# MKV46F16 register map
Vendor: Freescale Semiconductor, Inc.; Series: Kinetis_V; File version: 1.6
CPU: CM4 r0p1, little endian, no MPU, FPU, VTOR, 4 interrupt priority bits
Registers are 32-bit, read-write, reset 0x0 unless marked. A register's access mark holds for its fields unless they carry their own. Offsets are from the block's base; [hi:lo] are bit positions; {n}, {i} and the like mark numbered series; 'fields as' and 'values as' point back to an identical list.

## PWMA — Pulse Width Modulator with nano edge placement
Base 0x40033000; register names take the prefix PWMA_
{0x0+0x60*i} SM{i}CNT (i=0..3) 16-bit ro — Counter Register
  [15:0] CNT — Counter Register Bits
{0x2+0x60*i} SM{i}INIT (i=0..3) 16-bit — Initial Count Register
  [15:0] INIT — Initial Count Register Bits
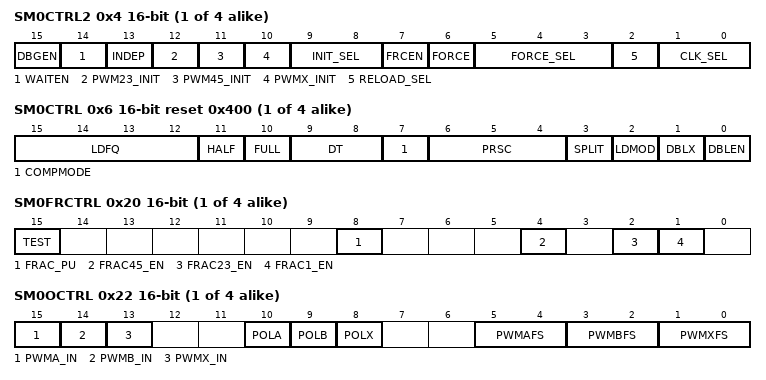
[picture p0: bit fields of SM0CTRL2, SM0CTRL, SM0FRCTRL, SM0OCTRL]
{0x4+0x60*i} SM{i}CTRL2 (i=0..3) 16-bit — Control 2 Register
  [15] DBGEN — Debug Enable
  [14] WAITEN — WAIT Enable
  [13] INDEP — Independent or Complementary Pair Operation
    0=PWM_A and PWM_B form a complementary PWM pair; 1=PWM_A and PWM_B outputs are independent PWMs
  [12] PWM23_INIT — PWM23 Initial Value
  [11] PWM45_INIT — PWM45 Initial Value
  [10] PWMX_INIT — PWM_X Initial Value
  [9:8] INIT_SEL — Initialization Control Select
    0=Local sync (PWM_X) causes initialization; 1=Master reload from submodule 0 causes initialization. This setting should not be used in submodule 0 as it will force the INIT signal to logic 0. The submodule counter will only reinitialize when a master reload occurs.; 2=Master sync from submodule 0 causes initialization. This setting should not be used in submodule 0 as it will force the INIT signal to logic 0.; 3=EXT_SYNC causes initialization
  [7] FRCEN — Force Initialization Enable
    0=Initialization from a FORCE_OUT event is disabled; 1=Initialization from a FORCE_OUT event is enabled
  [6] FORCE wo — Force Initialization
  [5:3] FORCE_SEL — This read/write bit determines the source of the FORCE OUTPUT signal for this submodule.
    0=The local force signal, CTRL2[FORCE], from this submodule is used to force updates; 1=The master force signal from submodule 0 is used to force updates. This setting should not be used in submodule 0 as it will hold the FORCE OUTPUT signal to logic 0.; 2=The local reload signal from this submodule is used to force updates without regard to the state of LDOK; 3=The master reload signal from submodule0 is used to force updates if LDOK is set. This setting should not be used in submodule0 as it will hold the FORCE OUTPUT signal to logic 0.; 4=The local sync signal from this submodule is used to force updates; 5=The master sync signal from submodule0 is used to force updates. This setting should not be used in submodule0 as it will hold the FORCE OUTPUT signal to logic 0.; 6=The external force signal, EXT_FORCE, from outside the PWM module causes updates; 7=The external sync signal, EXT_SYNC, from outside the PWM module causes updates
  [2] RELOAD_SEL — Reload Source Select
    0=The local RELOAD signal is used to reload registers; 1=The master RELOAD signal (from submodule 0) is used to reload registers. This setting should not be used in submodule 0 as it will force the RELOAD signal to logic 0.
  [1:0] CLK_SEL — Clock Source Select
    0=The IPBus clock is used as the clock for the local prescaler and counter; 1=EXT_CLK is used as the clock for the local prescaler and counter; 2=Submodule 0's clock (AUX_CLK) is used as the source clock for the local prescaler and counter. This setting should not be used in submodule 0 as it will force the clock to logic 0.
{0x6+0x60*i} SM{i}CTRL (i=0..3) 16-bit reset 0x400 — Control Register
  [15:12] LDFQ — These buffered read/write bits select the PWM load frequency
    0=Every PWM opportunity; {v}=Every {v+1} PWM opportunities (v=1..15)
  [11] HALF — Half Cycle Reload
    0=Half-cycle reloads disabled; 1=Half-cycle reloads enabled
  [10] FULL — Full Cycle Reload
    0=Full-cycle reloads disabled; 1=Full-cycle reloads enabled
  [9:8] DT ro — Deadtime
  [7] COMPMODE — Compare Mode
    0=The VAL* registers and the PWM counter are compared using an "equal to" method. This means that PWM edges are only produced when the counter is equal to one of the VAL* register values. This implies that a PWMA output that is high at the end of a period will maintain this state until a match with VAL3 clears the output in the following period.; 1=The VAL* registers and the PWM counter are compared using an "equal to or greater than" method. This means that PWM edges are produced when the counter is equal to or greater than one of the VAL* register values. This implies that a PWMA output that is high at the end of a period could go low at the start of the next period if the starting counter value is greater than (but not necessarily equal to) the new VAL3 value.
  [6:4] PRSC — Prescaler
    0=PWM clock frequency = fclk; 1=PWM clock frequency = fclk/2; 2=PWM clock frequency = fclk/4; 3=PWM clock frequency = fclk/8; 4=PWM clock frequency = fclk/16; 5=PWM clock frequency = fclk/32; 6=PWM clock frequency = fclk/64; 7=PWM clock frequency = fclk/128
  [3] SPLIT — Split the DBLPWM signal to PWMA and PWMB
    0=DBLPWM is not split. PWMA and PWMB each have double pulses.; 1=DBLPWM is split to PWMA and PWMB
  [2] LDMOD — Load Mode Select
    0=Buffered registers of this submodule are loaded and take effect at the next PWM reload if MCTRL[LDOK] is set; 1=Buffered registers of this submodule are loaded and take effect immediately upon MCTRL[LDOK] being set. In this case it is not necessary to set CTRL[FULL] or CTRL[HALF].
  [1] DBLX — PWMX Double Switching Enable
    0=PWMX double pulse disabled; 1=PWMX double pulse enabled
  [0] DBLEN — Double Switching Enable
    0=Double switching disabled; 1=Double switching enabled
{0xA+0x60*i} SM{i}VAL0 (i=0..3) 16-bit — Value Register 0
  [15:0] VAL0
{0xC+0x60*i} SM{i}FRACVAL1 (i=0..3) 16-bit — Fractional Value Register 1
  [15:11] FRACVAL1 — Fractional Value 1 Register
{0xE+0x60*i} SM{i}VAL1 (i=0..3) 16-bit — Value Register 1
  [15:0] VAL1
{0x10+0x60*i} SM{i}FRACVAL2 (i=0..3) 16-bit — Fractional Value Register 2
  [15:11] FRACVAL2 — Fractional Value 2
{0x12+0x60*i} SM{i}VAL2 (i=0..3) 16-bit — Value Register 2
  [15:0] VAL2
{0x14+0x60*i} SM{i}FRACVAL3 (i=0..3) 16-bit — Fractional Value Register 3
  [15:11] FRACVAL3 — Fractional Value 3
{0x16+0x60*i} SM{i}VAL3 (i=0..3) 16-bit — Value Register 3
  [15:0] VAL3
{0x18+0x60*i} SM{i}FRACVAL4 (i=0..3) 16-bit — Fractional Value Register 4
  [15:11] FRACVAL4 — Fractional Value 4
{0x1A+0x60*i} SM{i}VAL4 (i=0..3) 16-bit — Value Register 4
  [15:0] VAL4
{0x1C+0x60*i} SM{i}FRACVAL5 (i=0..3) 16-bit — Fractional Value Register 5
  [15:11] FRACVAL5 — Fractional Value 5
{0x1E+0x60*i} SM{i}VAL5 (i=0..3) 16-bit — Value Register 5
  [15:0] VAL5
{0x20+0x60*i} SM{i}FRCTRL (i=0..3) 16-bit — Fractional Control Register
  [15] TEST ro — Test Status Bit
  [8] FRAC_PU — Fractional Delay Circuit Power Up
    0=Turn off fractional delay logic; 1=Power up fractional delay logic
  [4] FRAC45_EN — Fractional Cycle Placement Enable for PWM_B
    0=Disable fractional cycle placement for PWM_B; 1=Enable fractional cycle placement for PWM_B
  [2] FRAC23_EN — Fractional Cycle Placement Enable for PWM_A
    0=Disable fractional cycle placement for PWM_A; 1=Enable fractional cycle placement for PWM_A
  [1] FRAC1_EN — Fractional Cycle PWM Period Enable
    0=Disable fractional cycle length for the PWM period; 1=Enable fractional cycle length for the PWM period
{0x22+0x60*i} SM{i}OCTRL (i=0..3) 16-bit — Output Control Register
  [15] PWMA_IN ro — PWM_A Input
  [14] PWMB_IN ro — PWM_B Input
  [13] PWMX_IN ro — PWM_X Input
  [10] POLA — PWM_A Output Polarity
    0=PWM_A output not inverted. A high level on the PWM_A pin represents the "on" or "active" state.; 1=PWM_A output inverted. A low level on the PWM_A pin represents the "on" or "active" state.
  [9] POLB — PWM_B Output Polarity
    0=PWM_B output not inverted. A high level on the PWM_B pin represents the "on" or "active" state.; 1=PWM_B output inverted. A low level on the PWM_B pin represents the "on" or "active" state.
  [8] POLX — PWM_X Output Polarity
    0=PWM_X output not inverted. A high level on the PWM_X pin represents the "on" or "active" state.; 1=PWM_X output inverted. A low level on the PWM_X pin represents the "on" or "active" state.
  [5:4] PWMAFS — PWM_A Fault State
    0=Output is forced to logic 0 state prior to consideration of output polarity control; 1=Output is forced to logic 1 state prior to consideration of output polarity control; 2=Output is tristated; 3=Output is tristated
  [3:2] PWMBFS — PWM_B Fault State
    values as PWMAFS
  [1:0] PWMXFS — PWM_X Fault State
    values as PWMAFS
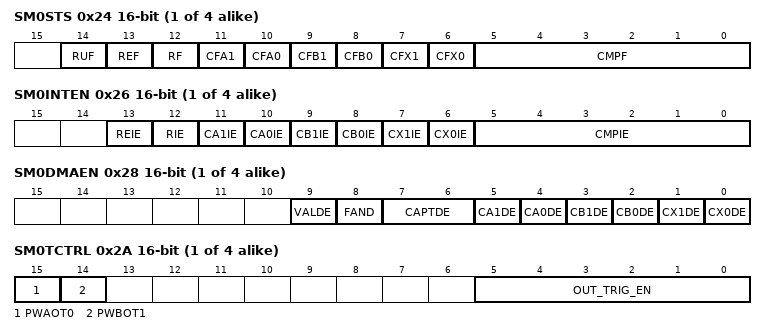
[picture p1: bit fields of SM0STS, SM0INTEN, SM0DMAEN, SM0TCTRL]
{0x24+0x60*i} SM{i}STS (i=0..3) 16-bit — Status Register
  [14] RUF ro — Registers Updated Flag
    0=No register update has occurred since last reload; 1=At least one of the double buffered registers has been updated since the last reload
  [13] REF — Reload Error Flag
    0=No reload error occurred; 1=Reload signal occurred with non-coherent data and MCTRL[LDOK] = 0
  [12] RF — Reload Flag
    0=No new reload cycle since last STS[RF] clearing; 1=New reload cycle since last STS[RF] clearing
  [11] CFA1 — Capture Flag A1
  [10] CFA0 — Capture Flag A0
  [9] CFB1 — Capture Flag B1
  [8] CFB0 — Capture Flag B0
  [7] CFX1 — Capture Flag X1
  [6] CFX0 — Capture Flag X0
  [5:0] CMPF — Compare Flags
    0=No compare event has occurred for a particular VALx value; 1=A compare event has occurred for a particular VALx value
{0x26+0x60*i} SM{i}INTEN (i=0..3) 16-bit — Interrupt Enable Register
  [13] REIE — Reload Error Interrupt Enable
    0=STS[REF] CPU interrupt requests disabled; 1=STS[REF] CPU interrupt requests enabled
  [12] RIE — Reload Interrupt Enable
    0=STS[RF] CPU interrupt requests disabled; 1=STS[RF] CPU interrupt requests enabled
  [11] CA1IE — Capture A 1 Interrupt Enable
    0=Interrupt request disabled for STS[CFA1]; 1=Interrupt request enabled for STS[CFA1]
  [10] CA0IE — Capture A 0 Interrupt Enable
    0=Interrupt request disabled for STS[CFA0]; 1=Interrupt request enabled for STS[CFA0]
  [9] CB1IE — Capture B 1 Interrupt Enable
    0=Interrupt request disabled for STS[CFB1]; 1=Interrupt request enabled for STS[CFB1]
  [8] CB0IE — Capture B 0 Interrupt Enable
    0=Interrupt request disabled for STS[CFB0]; 1=Interrupt request enabled for STS[CFB0]
  [7] CX1IE — Capture X 1 Interrupt Enable
    0=Interrupt request disabled for STS[CFX1]; 1=Interrupt request enabled for STS[CFX1]
  [6] CX0IE — Capture X 0 Interrupt Enable
    0=Interrupt request disabled for STS[CFX0]; 1=Interrupt request enabled for STS[CFX0]
  [5:0] CMPIE — Compare Interrupt Enables
    0=The corresponding STS[CMPF] bit will not cause an interrupt request; 1=The corresponding STS[CMPF] bit will cause an interrupt request
{0x28+0x60*i} SM{i}DMAEN (i=0..3) 16-bit — DMA Enable Register
  [9] VALDE — Value Registers DMA Enable
    0=DMA write requests disabled; 1=DMA write requests for the VALx and FRACVALx registers enabled
  [8] FAND — FIFO Watermark AND Control
    0=Selected FIFO watermarks are OR'ed together; 1=Selected FIFO watermarks are AND'ed together
  [7:6] CAPTDE — Capture DMA Enable Source Select
    0=Read DMA requests disabled; 1=Exceeding a FIFO watermark sets the DMA read request. This requires at least one of DMAEN[CA1DE], DMAEN[CA0DE], DMAEN[CB1DE], DMAEN[CB0DE], DMAEN[CX1DE], or DMAEN[CX0DE] to also be set in order to determine to which watermark(s) the DMA request is sensitive.; 2=A local sync (VAL1 matches counter) sets the read DMA request; 3=A local reload (STS[RF] being set) sets the read DMA request
  [5] CA1DE — Capture A1 FIFO DMA Enable
  [4] CA0DE — Capture A0 FIFO DMA Enable
  [3] CB1DE — Capture B1 FIFO DMA Enable
  [2] CB0DE — Capture B0 FIFO DMA Enable
  [1] CX1DE — Capture X1 FIFO DMA Enable
  [0] CX0DE — Capture X0 FIFO DMA Enable
{0x2A+0x60*i} SM{i}TCTRL (i=0..3) 16-bit — Output Trigger Control Register
  [15] PWAOT0 wo — Output Trigger 0 Source Select
    0=Route the PWM_OUT_TRIG0 signal to PWM_OUT_TRIG0 port; 1=Route the PWMA output to the PWM_OUT_TRIG0 port
  [14] PWBOT1 wo — Output Trigger 1 Source Select
    0=Route the PWM_OUT_TRIG1 signal to PWM_OUT_TRIG1 port; 1=Route the PWMB output to the PWM_OUT_TRIG1 port
  [5:0] OUT_TRIG_EN — Output Trigger Enables
    0=PWM_OUT_TRIGx will not set when the counter value matches the VALx value; 1=PWM_OUT_TRIGx will set when the counter value matches the VALx value
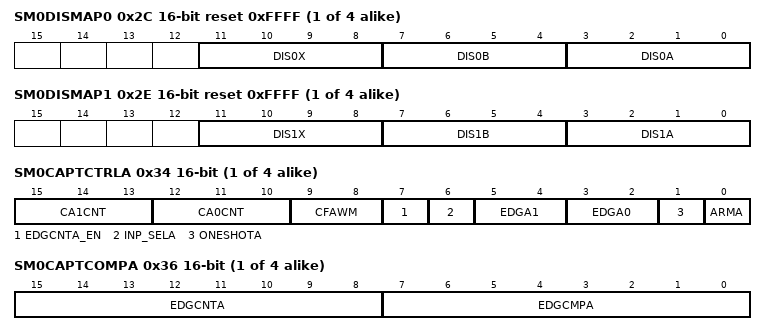
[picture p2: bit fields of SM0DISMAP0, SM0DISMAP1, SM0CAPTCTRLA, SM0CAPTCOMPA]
{0x2C+0x60*i} SM{i}DISMAP0 (i=0..3) 16-bit reset 0xFFFF — Fault Disable Mapping Register 0
  [11:8] DIS0X — PWM_X Fault Disable Mask 0
  [7:4] DIS0B — PWM_B Fault Disable Mask 0
  [3:0] DIS0A — PWM_A Fault Disable Mask 0
{0x2E+0x60*i} SM{i}DISMAP1 (i=0..3) 16-bit reset 0xFFFF — Fault Disable Mapping Register 1
  [11:8] DIS1X — PWM_X Fault Disable Mask 1
  [7:4] DIS1B — PWM_B Fault Disable Mask 1
  [3:0] DIS1A — PWM_A Fault Disable Mask 1
{0x30+0x60*i} SM{i}DTCNT0 (i=0..3) 16-bit reset 0x7FF — Deadtime Count Register 0
  [15:0] DTCNT0 — The DTCNT0 field is interpreted differently depending on whether or not the fractional delays are being used (FRCNTRL[FRAC23_EN] is set)
{0x32+0x60*i} SM{i}DTCNT1 (i=0..3) 16-bit reset 0x7FF — Deadtime Count Register 1
  [15:0] DTCNT1 — The DTCNT1 field is interpreted differently depending on whether or not the fractional delays are being used (FRCNTRL[FRAC45_EN] is set)
{0x34+0x60*i} SM{i}CAPTCTRLA (i=0..3) 16-bit — Capture Control A Register
  [15:13] CA1CNT ro — Capture A1 FIFO Word Count
  [12:10] CA0CNT ro — Capture A0 FIFO Word Count
  [9:8] CFAWM — Capture A FIFOs Water Mark
  [7] EDGCNTA_EN — Edge Counter A Enable
    0=Edge counter disabled and held in reset; 1=Edge counter enabled
  [6] INP_SELA — Input Select A
    0=Raw PWM_A input signal selected as source; 1=Output of edge counter/compare selected as source. When this bitfield is set to 1, the internal edge counter is enabled and the rising and/or falling edges specified by the CAPTCTRLA[EDGA0] and CAPTCTRLA[EDGA1] fields are ignored. The software must still place a value other than 00 in either or both of the CAPTCTLRA[EDGA0] and/or CAPTCTRLA[EDGA1] fields in order to enable one or both of the capture registers.
  [5:4] EDGA1 — Edge A 1
    0=Disabled; 1=Capture falling edges; 2=Capture rising edges; 3=Capture any edge
  [3:2] EDGA0 — Edge A 0
    values as EDGA1
  [1] ONESHOTA — One Shot Mode A
    0=Free running mode is selected. If both capture circuits are enabled, then capture circuit 0 is armed first after CAPTCTRLA[ARMA] is set. Once a capture occurs, capture circuit 0 is disarmed and capture circuit 1 is armed. After capture circuit 1 performs a capture, it is disarmed and capture circuit 0 is re-armed. The process continues indefinitely. If only one of the capture circuits is enabled, then captures continue indefinitely on the enabled capture circuit.; 1=One shot mode is selected. If both capture circuits are enabled, then capture circuit 0 is armed first after CAPTCTRLA[ARMA] is set. Once a capture occurs, capture circuit 0 is disarmed and capture circuit 1 is armed. After capture circuit 1 performs a capture, it is disarmed and CAPTCTRLA[ARMA] is cleared. No further captures will be performed until CAPTCTRLA[ARMA] is set again. If only one of the capture circuits is enabled, then a single capture will occur on the enabled capture circuit and CAPTCTRLA[ARMA] is then cleared.
  [0] ARMA
    0=Input capture operation is disabled; 1=Input capture operation as specified by CAPTCTRLA[EDGAx] is enabled
{0x36+0x60*i} SM{i}CAPTCOMPA (i=0..3) 16-bit — Capture Compare A Register
  [15:8] EDGCNTA ro — Edge Counter A
  [7:0] EDGCMPA — Edge Compare A
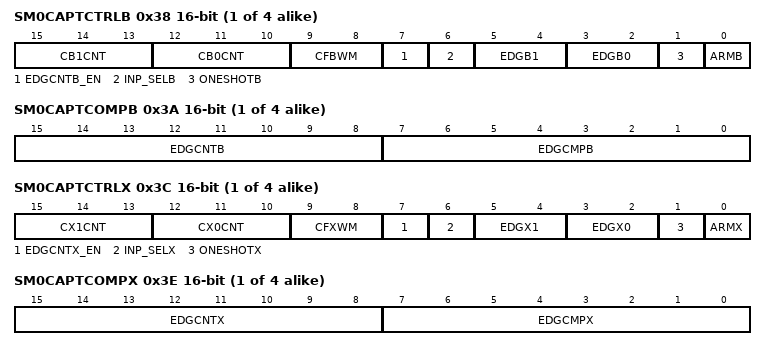
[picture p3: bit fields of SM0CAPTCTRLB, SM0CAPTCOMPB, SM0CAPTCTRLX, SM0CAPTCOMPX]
{0x38+0x60*i} SM{i}CAPTCTRLB (i=0..3) 16-bit — Capture Control B Register
  [15:13] CB1CNT ro — Capture B1 FIFO Word Count
  [12:10] CB0CNT ro — Capture B0 FIFO Word Count
  [9:8] CFBWM — Capture B FIFOs Water Mark
  [7] EDGCNTB_EN — Edge Counter B Enable
    values as SM0CAPTCTRLA.EDGCNTA_EN
  [6] INP_SELB — Input Select B
    0=Raw PWM_B input signal selected as source; 1=Output of edge counter/compare selected as source. When this bitfield is set to 1, the internal edge counter is enabled and the rising and/or falling edges specified by the CAPTCTRLB[EDGB0] and CAPTCTRLB[EDGB1] fields are ignored. The software must still place a value other than 00 in either or both of the CAPTCTLRB[EDGB0] and/or CAPTCTRLB[EDGB1] fields in order to enable one or both of the capture registers.
  [5:4] EDGB1 — Edge B 1
    values as SM0CAPTCTRLA.EDGA1
  [3:2] EDGB0 — Edge B 0
    values as SM0CAPTCTRLA.EDGA1
  [1] ONESHOTB — One Shot Mode B
    0=Free running mode is selected. If both capture circuits are enabled, then capture circuit 0 is armed first after CAPTCTRLB[ARMB] is set. Once a capture occurs, capture circuit 0 is disarmed and capture circuit 1 is armed. After capture circuit 1 performs a capture, it is disarmed and capture circuit 0 is re-armed. The process continues indefinitely. If only one of the capture circuits is enabled, then captures continue indefinitely on the enabled capture circuit.; 1=One shot mode is selected. If both capture circuits are enabled, then capture circuit 0 is armed first after CAPTCTRLB[ARMB] is set. Once a capture occurs, capture circuit 0 is disarmed and capture circuit 1 is armed. After capture circuit 1 performs a capture, it is disarmed and CAPTCTRLB[ARMB] is cleared. No further captures will be performed until CAPTCTRLB[ARMB] is set again. If only one of the capture circuits is enabled, then a single capture will occur on the enabled capture circuit and CAPTCTRLB[ARMB] is then cleared.
  [0] ARMB
    0=Input capture operation is disabled; 1=Input capture operation as specified by CAPTCTRLB[EDGBx] is enabled
{0x3A+0x60*i} SM{i}CAPTCOMPB (i=0..3) 16-bit — Capture Compare B Register
  [15:8] EDGCNTB ro — Edge Counter B
  [7:0] EDGCMPB — Edge Compare B
{0x3C+0x60*i} SM{i}CAPTCTRLX (i=0..3) 16-bit — Capture Control X Register
  [15:13] CX1CNT ro — Capture X1 FIFO Word Count
  [12:10] CX0CNT ro — Capture X0 FIFO Word Count
  [9:8] CFXWM — Capture X FIFOs Water Mark
  [7] EDGCNTX_EN — Edge Counter X Enable
    values as SM0CAPTCTRLA.EDGCNTA_EN
  [6] INP_SELX — Input Select X
    0=Raw PWM_X input signal selected as source; 1=Output of edge counter/compare selected as source. When this bitfield is set to 1, the internal edge counter is enabled and the rising and/or falling edges specified by the CAPTCTRLX[EDGX0] and CAPTCTRLX[EDGX1] fields are ignored. The software must still place a value other than 00 in either or both of the CAPTCTLRX[EDGX0] and/or CAPTCTRLX[EDGX1] fields in order to enable one or both of the capture registers.
  [5:4] EDGX1 — Edge X 1
    values as SM0CAPTCTRLA.EDGA1
  [3:2] EDGX0 — Edge X 0
    values as SM0CAPTCTRLA.EDGA1
  [1] ONESHOTX — One Shot Mode Aux
    0=Free running mode is selected. If both capture circuits are enabled, then capture circuit 0 is armed first after the ARMX bit is set. Once a capture occurs, capture circuit 0 is disarmed and capture circuit 1 is armed. After capture circuit 1 performs a capture, it is disarmed and capture circuit 0 is re-armed. The process continues indefinitely. If only one of the capture circuits is enabled, then captures continue indefinitely on the enabled capture circuit.; 1=One shot mode is selected. If both capture circuits are enabled, then capture circuit 0 is armed first after the ARMX bit is set. Once a capture occurs, capture circuit 0 is disarmed and capture circuit 1 is armed. After capture circuit 1 performs a capture, it is disarmed and the ARMX bit is cleared. No further captures will be performed until the ARMX bit is set again. If only one of the capture circuits is enabled, then a single capture will occur on the enabled capture circuit and the ARMX bit is then cleared.
  [0] ARMX
    0=Input capture operation is disabled; 1=Input capture operation as specified by CAPTCTRLX[EDGXx] is enabled
{0x3E+0x60*i} SM{i}CAPTCOMPX (i=0..3) 16-bit — Capture Compare X Register
  [15:8] EDGCNTX ro — Edge Counter X
  [7:0] EDGCMPX — Edge Compare X
{0x40+0x60*i} SM{i}CVAL0 (i=0..3) 16-bit ro — Capture Value 0 Register
  [15:0] CAPTVAL0 — This read-only register stores the value captured from the submodule counter
{0x42+0x60*i} SM{i}CVAL0CYC (i=0..3) 16-bit ro — Capture Value 0 Cycle Register
  [3:0] CVAL0CYC — This read-only register stores the cycle number corresponding to the value captured in CVAL0
{0x44+0x60*i} SM{i}CVAL1 (i=0..3) 16-bit ro — Capture Value 1 Register
  [15:0] CAPTVAL1 — This read-only register stores the value captured from the submodule counter
{0x46+0x60*i} SM{i}CVAL1CYC (i=0..3) 16-bit ro — Capture Value 1 Cycle Register
  [3:0] CVAL1CYC — This read-only register stores the cycle number corresponding to the value captured in CVAL1
{0x48+0x60*i} SM{i}CVAL2 (i=0..3) 16-bit ro — Capture Value 2 Register
  [15:0] CAPTVAL2 — This read-only register stores the value captured from the submodule counter
{0x4A+0x60*i} SM{i}CVAL2CYC (i=0..3) 16-bit ro — Capture Value 2 Cycle Register
  [3:0] CVAL2CYC — This read-only register stores the cycle number corresponding to the value captured in CVAL2
{0x4C+0x60*i} SM{i}CVAL3 (i=0..3) 16-bit ro — Capture Value 3 Register
  [15:0] CAPTVAL3 — This read-only register stores the value captured from the submodule counter
{0x4E+0x60*i} SM{i}CVAL3CYC (i=0..3) 16-bit ro — Capture Value 3 Cycle Register
  [3:0] CVAL3CYC — This read-only register stores the cycle number corresponding to the value captured in CVAL3
{0x50+0x60*i} SM{i}CVAL4 (i=0..3) 16-bit ro — Capture Value 4 Register
  [15:0] CAPTVAL4 — This read-only register stores the value captured from the submodule counter
{0x52+0x60*i} SM{i}CVAL4CYC (i=0..3) 16-bit ro — Capture Value 4 Cycle Register
  [3:0] CVAL4CYC — This read-only register stores the cycle number corresponding to the value captured in CVAL4
{0x54+0x60*i} SM{i}CVAL5 (i=0..3) 16-bit ro — Capture Value 5 Register
  [15:0] CAPTVAL5 — This read-only register stores the value captured from the submodule counter
{0x56+0x60*i} SM{i}CVAL5CYC (i=0..3) 16-bit ro — Capture Value 5 Cycle Register
  [3:0] CVAL5CYC — This read-only register stores the cycle number corresponding to the value captured in CVAL5
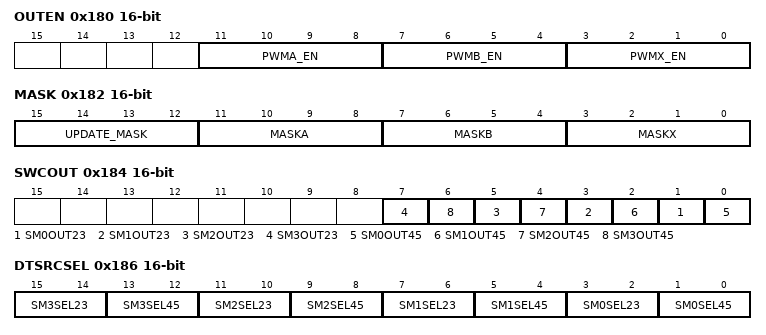
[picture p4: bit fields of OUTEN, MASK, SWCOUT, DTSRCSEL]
0x180 OUTEN 16-bit — Output Enable Register
  [11:8] PWMA_EN — PWM_A Output Enables
    0=PWM_A output disabled; 1=PWM_A output enabled
  [7:4] PWMB_EN — PWM_B Output Enables
    0=PWM_B output disabled; 1=PWM_B output enabled
  [3:0] PWMX_EN — PWM_X Output Enables
    0=PWM_X output disabled; 1=PWM_X output enabled
0x182 MASK 16-bit
  [15:12] UPDATE_MASK wo — Update Mask Bits Immediately
    0=Normal operation. MASK* bits within the corresponding submodule are not updated until a FORCE_OUT event occurs within the submodule.; 1=Immediate operation. MASK* bits within the corresponding submodule are updated on the following clock edge after setting this bit.
  [11:8] MASKA — PWM_A Masks
    0=PWM_A output normal; 1=PWM_A output masked
  [7:4] MASKB — PWM_B Masks
    0=PWM_B output normal; 1=PWM_B output masked
  [3:0] MASKX — PWM_X Masks
    0=PWM_X output normal; 1=PWM_X output masked
0x184 SWCOUT 16-bit — Software Controlled Output Register
  [2n+1] SM{n}OUT23 (n=0..3) — Submodule {n} Software Controlled Output 23
    0=A logic 0 is supplied to the deadtime generator of submodule {n} instead of PWM23; 1=A logic 1 is supplied to the deadtime generator of submodule {n} instead of PWM23
  [2n] SM{n}OUT45 (n=0..3) — Submodule {n} Software Controlled Output 45
    0=A logic 0 is supplied to the deadtime generator of submodule {n} instead of PWM45; 1=A logic 1 is supplied to the deadtime generator of submodule {n} instead of PWM45
0x186 DTSRCSEL 16-bit — PWM Source Select Register
  [4n+3:4n+2] SM{n}SEL23 (n=0..3) — Submodule {n} PWM23 Control Select
    0=Generated SM{n}PWM23 signal is used by the deadtime logic; 1=Inverted generated SM{n}PWM23 signal is used by the deadtime logic; 2=SWCOUT[SM{n}OUT23] is used by the deadtime logic; 3=PWM{n}_EXTA signal is used by the deadtime logic
  [4n+1:4n] SM{n}SEL45 (n=0..3) — Submodule {n} PWM45 Control Select
    0=Generated SM{n}PWM45 signal is used by the deadtime logic; 1=Inverted generated SM{n}PWM45 signal is used by the deadtime logic; 2=SWCOUT[SM{n}OUT45] is used by the deadtime logic; 3=PWM{n}_EXTB signal is used by the deadtime logic
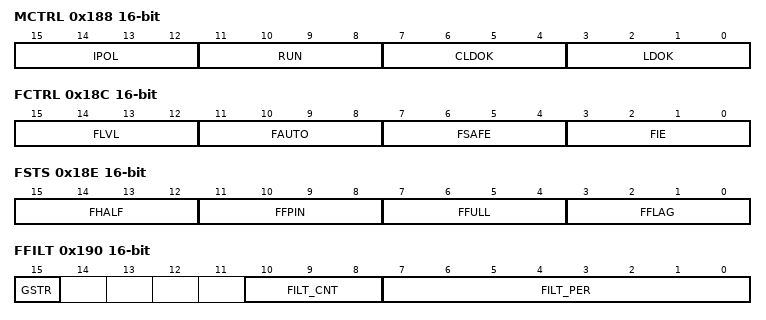
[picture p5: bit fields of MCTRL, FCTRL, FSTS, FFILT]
0x188 MCTRL 16-bit — Master Control Register
  [15:12] IPOL — Current Polarity
    0=PWM23 is used to generate complementary PWM pair in the corresponding submodule; 1=PWM45 is used to generate complementary PWM pair in the corresponding submodule
  [11:8] RUN
    0=PWM generator is disabled in the corresponding submodule; 1=PWM generator is enabled in the corresponding submodule
  [7:4] CLDOK wo — Clear Load Okay
  [3:0] LDOK — Load Okay
    0=Do not load new values; 1=Load prescaler, modulus, and PWM values of the corresponding submodule
0x18A MCTRL2 16-bit — Master Control 2 Register
  [1:0] MONPLL — Monitor PLL State
    0=Not locked. Do not monitor PLL operation. Resetting of the fractional delay block in case of PLL losing lock will be controlled by software.; 1=Not locked. Monitor PLL operation to automatically disable the fractional delay block when the PLL encounters problems.; 2=Locked. Do not monitor PLL operation. Resetting of the fractional delay block in case of PLL losing lock will be controlled by software. These bits are write protected until the next reset.; 3=Locked. Monitor PLL operation to automatically disable the fractional delay block when the PLL encounters problems. These bits are write protected until the next reset.
0x18C FCTRL 16-bit — Fault Control Register
  [15:12] FLVL — Fault Level
    0=A logic 0 on the fault input indicates a fault condition; 1=A logic 1 on the fault input indicates a fault condition
  [11:8] FAUTO — Automatic Fault Clearing
    0=Manual fault clearing. PWM outputs disabled by this fault are not enabled until FSTS[FFLAGx] is clear at the start of a half cycle or full cycle depending the state of FSTS[FFULL]. This is further controlled by FCTRL[FSAFE].; 1=Automatic fault clearing. PWM outputs disabled by this fault are enabled when FSTS[FFPINx] is clear at the start of a half cycle or full cycle depending on the state of FSTS[FFULL] without regard to the state of FSTS[FFLAGx].
  [7:4] FSAFE — Fault Safety Mode
    0=Normal mode. PWM outputs disabled by this fault are not enabled until FSTS[FFLAGx] is clear at the start of a half cycle or full cycle depending on the state of FSTS[FFULL] without regard to the state of FSTS[FFPINx]. The PWM outputs disabled by this fault input will not be re-enabled until the actual FAULTx input signal de-asserts since the fault input will combinationally disable the PWM outputs (as programmed in DISMAPn).; 1=Safe mode. PWM outputs disabled by this fault are not enabled until FSTS[FFLAGx] is clear and FSTS[FFPINx] is clear at the start of a half cycle or full cycle depending on the state of FSTS[FFULL].
  [3:0] FIE — Fault Interrupt Enables
    0=FAULTx CPU interrupt requests disabled; 1=FAULTx CPU interrupt requests enabled
0x18E FSTS 16-bit — Fault Status Register
  [15:12] FHALF — Half Cycle Fault Recovery
    0=PWM outputs are not re-enabled at the start of a half cycle; 1=PWM outputs are re-enabled at the start of a half cycle (as defined by VAL0)
  [11:8] FFPIN ro — Filtered Fault Pins
  [7:4] FFULL — Full Cycle
    0=PWM outputs are not re-enabled at the start of a full cycle; 1=PWM outputs are re-enabled at the start of a full cycle
  [3:0] FFLAG — Fault Flags
    0=No fault on the FAULTx pin; 1=Fault on the FAULTx pin
0x190 FFILT 16-bit — Fault Filter Register
  [15] GSTR — Fault Glitch Stretch Enable
    0=Fault input glitch stretching is disabled; 1=Input fault signals will be stretched to at least 2 IPBus clock cycles
  [10:8] FILT_CNT — Fault Filter Count
  [7:0] FILT_PER — Fault Filter Period
0x192 FTST 16-bit — Fault Test Register
  [0] FTEST — Fault Test
    0=No fault; 1=Cause a simulated fault
0x194 FCTRL2 16-bit — Fault Control 2 Register
  [3:0] NOCOMB — No Combinational Path From Fault Input To PWM Output
    0=There is a combinational link from the fault inputs to the PWM outputs. The fault inputs are combined with the filtered and latched fault signals to disable the PWM outputs.; 1=The direct combinational path from the fault inputs to the PWM outputs is disabled and the filtered and latched fault signals are used to disable the PWM outputs

## Notices in the file
Redistribution and use in source and binary forms, with or without modification,
are permitted provided that the following conditions are met:
o Redistributions of source code must retain the above copyright notice, this list
of conditions and the following disclaimer.
o Redistributions in binary form must reproduce the above copyright notice, this
list of conditions and the following disclaimer in the documentation and/or
other materials provided with the distribution.
o Neither the name of Freescale Semiconductor, Inc. nor the names of its
contributors may be used to endorse or promote products derived from this
software without specific prior written permission.
THIS SOFTWARE IS PROVIDED BY THE COPYRIGHT HOLDERS AND CONTRIBUTORS "AS IS" AND
ANY EXPRESS OR IMPLIED WARRANTIES, INCLUDING, BUT NOT LIMITED TO, THE IMPLIED
WARRANTIES OF MERCHANTABILITY AND FITNESS FOR A PARTICULAR PURPOSE ARE
DISCLAIMED. IN NO EVENT SHALL THE COPYRIGHT HOLDER OR CONTRIBUTORS BE LIABLE FOR
ANY DIRECT, INDIRECT, INCIDENTAL, SPECIAL, EXEMPLARY, OR CONSEQUENTIAL DAMAGES
(INCLUDING, BUT NOT LIMITED TO, PROCUREMENT OF SUBSTITUTE GOODS OR SERVICES;
LOSS OF USE, DATA, OR PROFITS; OR BUSINESS INTERRUPTION) HOWEVER CAUSED AND ON
ANY THEORY OF LIABILITY, WHETHER IN CONTRACT, STRICT LIABILITY, OR TORT
(INCLUDING NEGLIGENCE OR OTHERWISE) ARISING IN ANY WAY OUT OF THE USE OF THIS
SOFTWARE, EVEN IF ADVISED OF THE POSSIBILITY OF SUCH DAMAGE.
